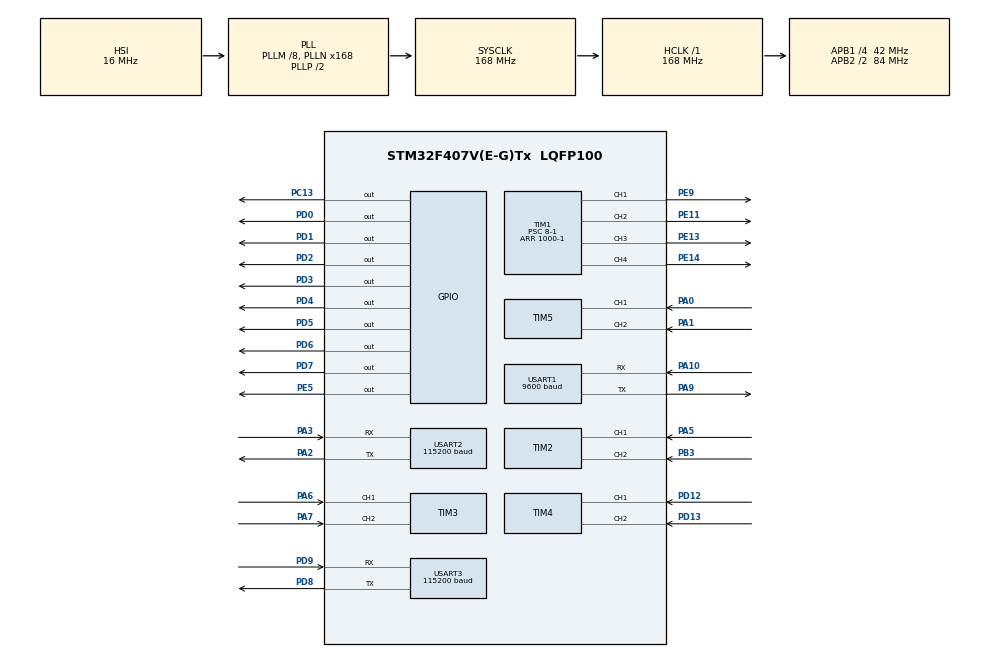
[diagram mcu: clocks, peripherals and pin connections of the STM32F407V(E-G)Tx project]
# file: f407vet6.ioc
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Dma.Request0=USART1_RX
Dma.Request1=USART1_TX
Dma.Request2=USART2_RX
Dma.Request3=USART2_TX
Dma.USART1_RX.0.Direction=DMA_PERIPH_TO_MEMORY
Dma.USART1_RX.0.FIFOMode=DMA_FIFOMODE_DISABLE
Dma.USART1_RX.0.Instance=DMA2_Stream2
Dma.USART1_RX.0.MemDataAlignment=DMA_MDATAALIGN_BYTE
Dma.USART1_RX.0.MemInc=DMA_MINC_ENABLE
Dma.USART1_RX.0.Mode=DMA_CIRCULAR
Dma.USART1_RX.0.PeriphDataAlignment=DMA_PDATAALIGN_BYTE
Dma.USART1_RX.0.PeriphInc=DMA_PINC_DISABLE
Dma.USART1_RX.0.Priority=DMA_PRIORITY_LOW
Dma.USART1_TX.1.Direction=DMA_MEMORY_TO_PERIPH
Dma.USART1_TX.1.FIFOMode=DMA_FIFOMODE_DISABLE
Dma.USART1_TX.1.Instance=DMA2_Stream7
Dma.USART1_TX.1.MemDataAlignment=DMA_MDATAALIGN_BYTE
Dma.USART1_TX.1.MemInc=DMA_MINC_ENABLE
Dma.USART1_TX.1.Mode=DMA_NORMAL
Dma.USART1_TX.1.PeriphDataAlignment=DMA_PDATAALIGN_BYTE
Dma.USART1_TX.1.PeriphInc=DMA_PINC_DISABLE
Dma.USART1_TX.1.Priority=DMA_PRIORITY_LOW
Dma.USART2_RX.2.Direction=DMA_PERIPH_TO_MEMORY
Dma.USART2_RX.2.FIFOMode=DMA_FIFOMODE_DISABLE
Dma.USART2_RX.2.Instance=DMA1_Stream5
Dma.USART2_RX.2.MemDataAlignment=DMA_MDATAALIGN_BYTE
Dma.USART2_RX.2.MemInc=DMA_MINC_ENABLE
Dma.USART2_RX.2.Mode=DMA_CIRCULAR
Dma.USART2_RX.2.PeriphDataAlignment=DMA_PDATAALIGN_BYTE
Dma.USART2_RX.2.PeriphInc=DMA_PINC_DISABLE
Dma.USART2_RX.2.Priority=DMA_PRIORITY_LOW
Dma.USART2_TX.3.Direction=DMA_MEMORY_TO_PERIPH
Dma.USART2_TX.3.FIFOMode=DMA_FIFOMODE_DISABLE
Dma.USART2_TX.3.Instance=DMA1_Stream6
Dma.USART2_TX.3.MemDataAlignment=DMA_MDATAALIGN_BYTE
Dma.USART2_TX.3.MemInc=DMA_MINC_ENABLE
Dma.USART2_TX.3.Mode=DMA_NORMAL
Dma.USART2_TX.3.PeriphDataAlignment=DMA_PDATAALIGN_BYTE
Dma.USART2_TX.3.PeriphInc=DMA_PINC_DISABLE
Dma.USART2_TX.3.Priority=DMA_PRIORITY_LOW
FREERTOS.MEMORY_ALLOCATION=1
FREERTOS.Tasks01=MonitorTask,8,512,RTOS_Monitor_StartTask,As weak,NULL,Static,MonitorTaskStack,MonitorTaskTCB;ControlTask,48,1024,RTOS_Control_StartTask,As weak,NULL,Static,ControlTaskStack,ControlTaskTCB;UARTTask,24,1024,RTOS_UART_StartTask,As weak,NULL,Static,UARTTaskStack,UARTTaskTCB
Mcu.Family=STM32F4
Mcu.Name=STM32F407V(E-G)Tx
Mcu.Package=LQFP100
NVIC.DMA1_Stream5_IRQn=true\:5\:0\:false\:false\:true\:true\:false\:true\:true
NVIC.DMA1_Stream6_IRQn=true\:5\:0\:false\:false\:true\:true\:false\:true\:true
NVIC.DMA2_Stream2_IRQn=true\:5\:0\:false\:false\:true\:true\:false\:true\:true
NVIC.DMA2_Stream7_IRQn=true\:5\:0\:false\:false\:true\:true\:false\:true\:true
NVIC.PriorityGroup=NVIC_PRIORITYGROUP_4
NVIC.TIM7_IRQn=true\:15\:0\:false\:false\:true\:false\:false\:true\:true
NVIC.TimeBase=TIM7_IRQn
NVIC.TimeBaseIP=TIM7
NVIC.USART1_IRQn=true\:5\:0\:false\:false\:true\:true\:true\:true\:true
NVIC.USART2_IRQn=true\:5\:0\:false\:false\:true\:true\:true\:true\:true
NVIC.USART3_IRQn=true\:5\:0\:false\:false\:true\:true\:true\:true\:true
PA0-WKUP.Signal=S_TIM5_CH1
PA1.Signal=S_TIM5_CH2
PA10.Mode=Asynchronous
PA10.Signal=USART1_RX
PA13.Mode=Serial_Wire
PA13.Signal=SYS_JTMS-SWDIO
PA14.Mode=Serial_Wire
PA14.Signal=SYS_JTCK-SWCLK
PA2.Mode=Asynchronous
PA2.Signal=USART2_TX
PA3.Mode=Asynchronous
PA3.Signal=USART2_RX
PA5.Signal=S_TIM2_CH1_ETR
PA6.Signal=S_TIM3_CH1
PA7.Signal=S_TIM3_CH2
PA9.Mode=Asynchronous
PA9.Signal=USART1_TX
PB3.Signal=S_TIM2_CH2
PC13-ANTI_TAMP.Signal=GPIO_Output
PD0.Signal=GPIO_Output
PD1.Signal=GPIO_Output
PD12.Signal=S_TIM4_CH1
PD13.Signal=S_TIM4_CH2
PD2.Signal=GPIO_Output
PD3.Signal=GPIO_Output
PD4.Signal=GPIO_Output
PD5.Signal=GPIO_Output
PD6.Signal=GPIO_Output
PD7.Signal=GPIO_Output
PD8.Mode=Asynchronous
PD8.Signal=USART3_TX
PD9.Mode=Asynchronous
PD9.Signal=USART3_RX
PE11.Signal=S_TIM1_CH2
PE13.Signal=S_TIM1_CH3
PE14.Signal=S_TIM1_CH4
PE5.Signal=GPIO_Output
PE9.Signal=S_TIM1_CH1
PH0-OSC_IN.Mode=HSE-External-Oscillator
PH0-OSC_IN.Signal=RCC_OSC_IN
PH1-OSC_OUT.Mode=HSE-External-Oscillator
PH1-OSC_OUT.Signal=RCC_OSC_OUT
ProjectManager.HeapSize=0x200
ProjectManager.StackSize=0x400
ProjectManager.TargetToolchain=CMake
RCC.48MHZClocksFreq_Value=84000000
RCC.AHBFreq_Value=168000000
RCC.APB1CLKDivider=RCC_HCLK_DIV4
RCC.APB1Freq_Value=42000000
RCC.APB1TimFreq_Value=84000000
RCC.APB2CLKDivider=RCC_HCLK_DIV2
RCC.APB2Freq_Value=84000000
RCC.APB2TimFreq_Value=168000000
RCC.CortexFreq_Value=168000000
RCC.HCLKFreq_Value=168000000
RCC.HSE_VALUE=25000000
RCC.HSI_VALUE=16000000
RCC.LSE_VALUE=32768
RCC.PLLM=8
RCC.PLLN=168
RCC.SYSCLKFreq_VALUE=168000000
RCC.SYSCLKSource=RCC_SYSCLKSOURCE_PLLCLK
RCC.VCOOutputFreq_Value=336000000
SH.S_TIM1_CH1.0=TIM1_CH1,PWM Generation1 CH1
SH.S_TIM1_CH2.0=TIM1_CH2,PWM Generation2 CH2
SH.S_TIM1_CH3.0=TIM1_CH3,PWM Generation3 CH3
SH.S_TIM1_CH4.0=TIM1_CH4,PWM Generation4 CH4
SH.S_TIM2_CH1_ETR.0=TIM2_CH1,Encoder_Interface
SH.S_TIM2_CH2.0=TIM2_CH2,Encoder_Interface
SH.S_TIM3_CH1.0=TIM3_CH1,Encoder_Interface
SH.S_TIM3_CH2.0=TIM3_CH2,Encoder_Interface
SH.S_TIM4_CH1.0=TIM4_CH1,Encoder_Interface
SH.S_TIM4_CH2.0=TIM4_CH2,Encoder_Interface
SH.S_TIM5_CH1.0=TIM5_CH1,Encoder_Interface
SH.S_TIM5_CH2.0=TIM5_CH2,Encoder_Interface
TIM1.Channel-PWM\ Generation1\ CH1=TIM_CHANNEL_1
TIM1.Channel-PWM\ Generation2\ CH2=TIM_CHANNEL_2
TIM1.Channel-PWM\ Generation3\ CH3=TIM_CHANNEL_3
TIM1.Channel-PWM\ Generation4\ CH4=TIM_CHANNEL_4
TIM1.Period=1000-1
TIM1.Prescaler=8-1
TIM2.EncoderMode=TIM_ENCODERMODE_TI12
TIM2.IC1Filter=15
TIM2.IC2Filter=15
TIM3.EncoderMode=TIM_ENCODERMODE_TI12
TIM3.IC1Filter=15
TIM3.IC2Filter=15
TIM4.EncoderMode=TIM_ENCODERMODE_TI12
TIM4.IC1Filter=15
TIM4.IC2Filter=15
TIM5.EncoderMode=TIM_ENCODERMODE_TI12
TIM5.IC1Filter=15
TIM5.IC2Filter=15
USART1.BaudRate=9600
USART1.VirtualMode=VM_ASYNC
USART2.BaudRate=115200
USART2.VirtualMode=VM_ASYNC
USART3.BaudRate=115200
USART3.VirtualMode=VM_ASYNC
VP_FREERTOS_VS_CMSIS_V2.Mode=CMSIS_V2
VP_SYS_VS_tim7.Mode=TIM7
VP_TIM1_VS_ClockSourceINT.Mode=Internal
board=custom

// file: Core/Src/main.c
/* USER CODE BEGIN Header */
/**
  ******************************************************************************
  * @file           : main.c
  * @brief          : Main program body
  ******************************************************************************
  * @attention
  *
  * Copyright (c) 2026 STMicroelectronics.
  * All rights reserved.
  *
  * This software is licensed under terms that can be found in the LICENSE file
  * in the root directory of this software component.
  * If no LICENSE file comes with this software, it is provided AS-IS.
  *
  ******************************************************************************
  */
/* USER CODE END Header */
#include "main.h"
#include "cmsis_os.h"
#include "dma.h"
#include "tim.h"
#include "usart.h"
#include "gpio.h"

/* USER CODE BEGIN Includes */
#include "app_car.h"
#include "rtos_tasks.h"
/* USER CODE END Includes */

void SystemClock_Config(void);
void MX_FREERTOS_Init(void);

int main(void)
{

  /* MCU Configuration--------------------------------------------------------*/

  /* Reset of all peripherals, Initializes the Flash interface and the Systick. */
  HAL_Init();

  /* Configure the system clock */
  SystemClock_Config();

  /* Initialize all configured peripherals */
  MX_GPIO_Init();
  MX_DMA_Init();
  MX_TIM1_Init();
  MX_USART1_UART_Init();
  MX_TIM2_Init();
  MX_TIM3_Init();
  MX_TIM4_Init();
  MX_TIM5_Init();
  MX_USART2_UART_Init();
  MX_USART3_UART_Init();
  /* USER CODE BEGIN 2 */

  // 在这里初始化小车
  if (!App_Car_Boot())
  {
    Error_Handler();
  }

  /* USER CODE END 2 */

  /* Init scheduler */
  osKernelInitialize();  /* Call init function for freertos objects (in cmsis_os2.c) */
  MX_FREERTOS_Init();

  // 在这里启动任务
  if (!RTOS_StartAllTasks())
  {
    Error_Handler();
  }

  /* Start scheduler */
  osKernelStart();

  /* We should never get here as control is now taken by the scheduler */

  /* Infinite loop */
  while (1)
  {

  }
}

void SystemClock_Config(void)
{
  RCC_OscInitTypeDef RCC_OscInitStruct = {0};
  RCC_ClkInitTypeDef RCC_ClkInitStruct = {0};

  /** Configure the main internal regulator output voltage
  */
  __HAL_RCC_PWR_CLK_ENABLE();
  __HAL_PWR_VOLTAGESCALING_CONFIG(PWR_REGULATOR_VOLTAGE_SCALE1);

  /** Initializes the RCC Oscillators according to the specified parameters
  * in the RCC_OscInitTypeDef structure.
  */
  RCC_OscInitStruct.OscillatorType = RCC_OSCILLATORTYPE_HSI;
  RCC_OscInitStruct.HSIState = RCC_HSI_ON;
  RCC_OscInitStruct.HSICalibrationValue = RCC_HSICALIBRATION_DEFAULT;
  RCC_OscInitStruct.PLL.PLLState = RCC_PLL_ON;
  RCC_OscInitStruct.PLL.PLLSource = RCC_PLLSOURCE_HSI;
  RCC_OscInitStruct.PLL.PLLM = 8;
  RCC_OscInitStruct.PLL.PLLN = 168;
  RCC_OscInitStruct.PLL.PLLP = RCC_PLLP_DIV2;
  RCC_OscInitStruct.PLL.PLLQ = 4;
  if (HAL_RCC_OscConfig(&RCC_OscInitStruct) != HAL_OK)
  {
    Error_Handler();
  }

  /** Initializes the CPU, AHB and APB buses clocks
  */
  RCC_ClkInitStruct.ClockType = RCC_CLOCKTYPE_HCLK|RCC_CLOCKTYPE_SYSCLK
                              |RCC_CLOCKTYPE_PCLK1|RCC_CLOCKTYPE_PCLK2;
  RCC_ClkInitStruct.SYSCLKSource = RCC_SYSCLKSOURCE_PLLCLK;
  RCC_ClkInitStruct.AHBCLKDivider = RCC_SYSCLK_DIV1;
  RCC_ClkInitStruct.APB1CLKDivider = RCC_HCLK_DIV4;
  RCC_ClkInitStruct.APB2CLKDivider = RCC_HCLK_DIV2;

  if (HAL_RCC_ClockConfig(&RCC_ClkInitStruct, FLASH_LATENCY_5) != HAL_OK)
  {
    Error_Handler();
  }
}

void HAL_TIM_PeriodElapsedCallback(TIM_HandleTypeDef *htim)
{
  if (htim->Instance == TIM7)
  {
    HAL_IncTick();
  }
}

void Error_Handler(void)
{
  __disable_irq();
  while (1)
  {
  }
}

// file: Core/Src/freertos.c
/* USER CODE BEGIN Header */
/**
  ******************************************************************************
  * File Name          : freertos.c
  * Description        : Code for freertos applications
  ******************************************************************************
  * @attention
  *
  * Copyright (c) 2026 STMicroelectronics.
  * All rights reserved.
  *
  * This software is licensed under terms that can be found in the LICENSE file
  * in the root directory of this software component.
  * If no LICENSE file comes with this software, it is provided AS-IS.
  *
  ******************************************************************************
  */
/* USER CODE END Header */

#include "FreeRTOS.h"
#include "task.h"
#include "main.h"
#include "cmsis_os.h"

void MX_FREERTOS_Init(void); /* (MISRA C 2004 rule 8.1) */

void MX_FREERTOS_Init(void) {

}
